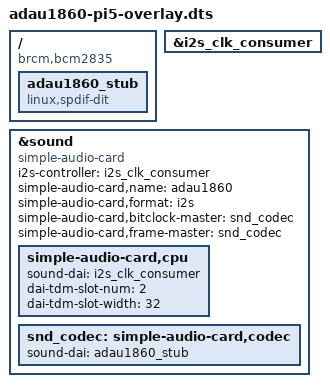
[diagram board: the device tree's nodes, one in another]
// SPDX-License-Identifier: GPL-2.0
//
// ADAU1860 on Raspberry Pi 5 / CM5 (RP1), codec as clock master.
//
// The ADAU1860 has NO ASoC codec driver in mainline or in ADI's kernel fork
// (verified 2026-09-02 against sound/soc/codecs/Kconfig in both trees).
// This overlay therefore uses the in-tree playback-only dummy codec
// "linux,spdif-dit" so the RP1 I2S block is brought up and a PCM device
// appears.  The ADAU1860 itself must be configured over I2C from userspace
// (i2c-dev) BEFORE audio will flow -- it has to be told to drive BCLK/FSYNC.
//
// CAPTURE IS NOT PROVIDED HERE.  "linux,spdif-dit" declares .playback only
// (sound/soc/codecs/spdif_transmitter.c); the capture-only twin is
// "linux,spdif-dir".  Getting simultaneous play + capture needs a real
// ADAU1860 codec driver -- see NOTES.md.
//
// Key point for Pi 5: GPIO18-21 can be driven by EITHER of two RP1 I2S
// blocks, and the choice is what selects clock direction:
//     i2s_clk_producer -> rp1_i2s0   (Pi drives BCLK/LRCLK)
//     i2s_clk_consumer -> rp1_i2s1   (codec drives BCLK/LRCLK)  <-- we want this
// Both aliases and their GPIO18-21 pinctrl are defined in
// arch/arm64/boot/dts/broadcom/bcm2712-rpi.dtsi.
//
// Build:   dtc -@ -I dts -O dtb -o adau1860-pi5.dtbo adau1860-pi5-overlay.dts
// Install: sudo cp adau1860-pi5.dtbo /boot/firmware/overlays/
// Enable:  add to /boot/firmware/config.txt:
//              dtparam=i2c_arm=on
//              dtoverlay=adau1860-pi5
//          and make sure no other audio overlay (or dtparam=audio=on) is
//          also claiming GPIO18-21.

/dts-v1/;
/plugin/;

/ {
	compatible = "brcm,bcm2835";

	// Bring up rp1_i2s1 -- the block that CONSUMES an external bit clock.
	fragment@0 {
		target = <&i2s_clk_consumer>;
		__overlay__ {
			status = "okay";
		};
	};

	// Placeholder codec. Replace with a real ADAU1860 node once a driver exists.
	fragment@1 {
		target-path = "/";
		__overlay__ {
			adau1860_stub: adau1860_stub {
				compatible = "linux,spdif-dit";
				#sound-dai-cells = <0>;
				status = "okay";
			};
		};
	};

	fragment@2 {
		target = <&sound>;
		__overlay__ {
			compatible = "simple-audio-card";
			i2s-controller = <&i2s_clk_consumer>;
			status = "okay";

			simple-audio-card,name = "adau1860";
			simple-audio-card,format = "i2s";

			// The CODEC owns both clocks. This is the whole point of the
			// overlay: it is what makes dw_i2s_set_fmt() ask for
			// SND_SOC_DAIFMT_BC_FC, which only rp1_i2s1 can satisfy.
			simple-audio-card,bitclock-master = <&snd_codec>;
			simple-audio-card,frame-master = <&snd_codec>;

			simple-audio-card,cpu {
				sound-dai = <&i2s_clk_consumer>;
				// Plain stereo I2S, 32-bit slots. For TDM, raise
				// slot-num to match what you program into the
				// ADAU1860 serial port (it supports up to TDM16).
				dai-tdm-slot-num = <2>;
				dai-tdm-slot-width = <32>;
			};

			snd_codec: simple-audio-card,codec {
				sound-dai = <&adau1860_stub>;
			};
		};
	};
};
